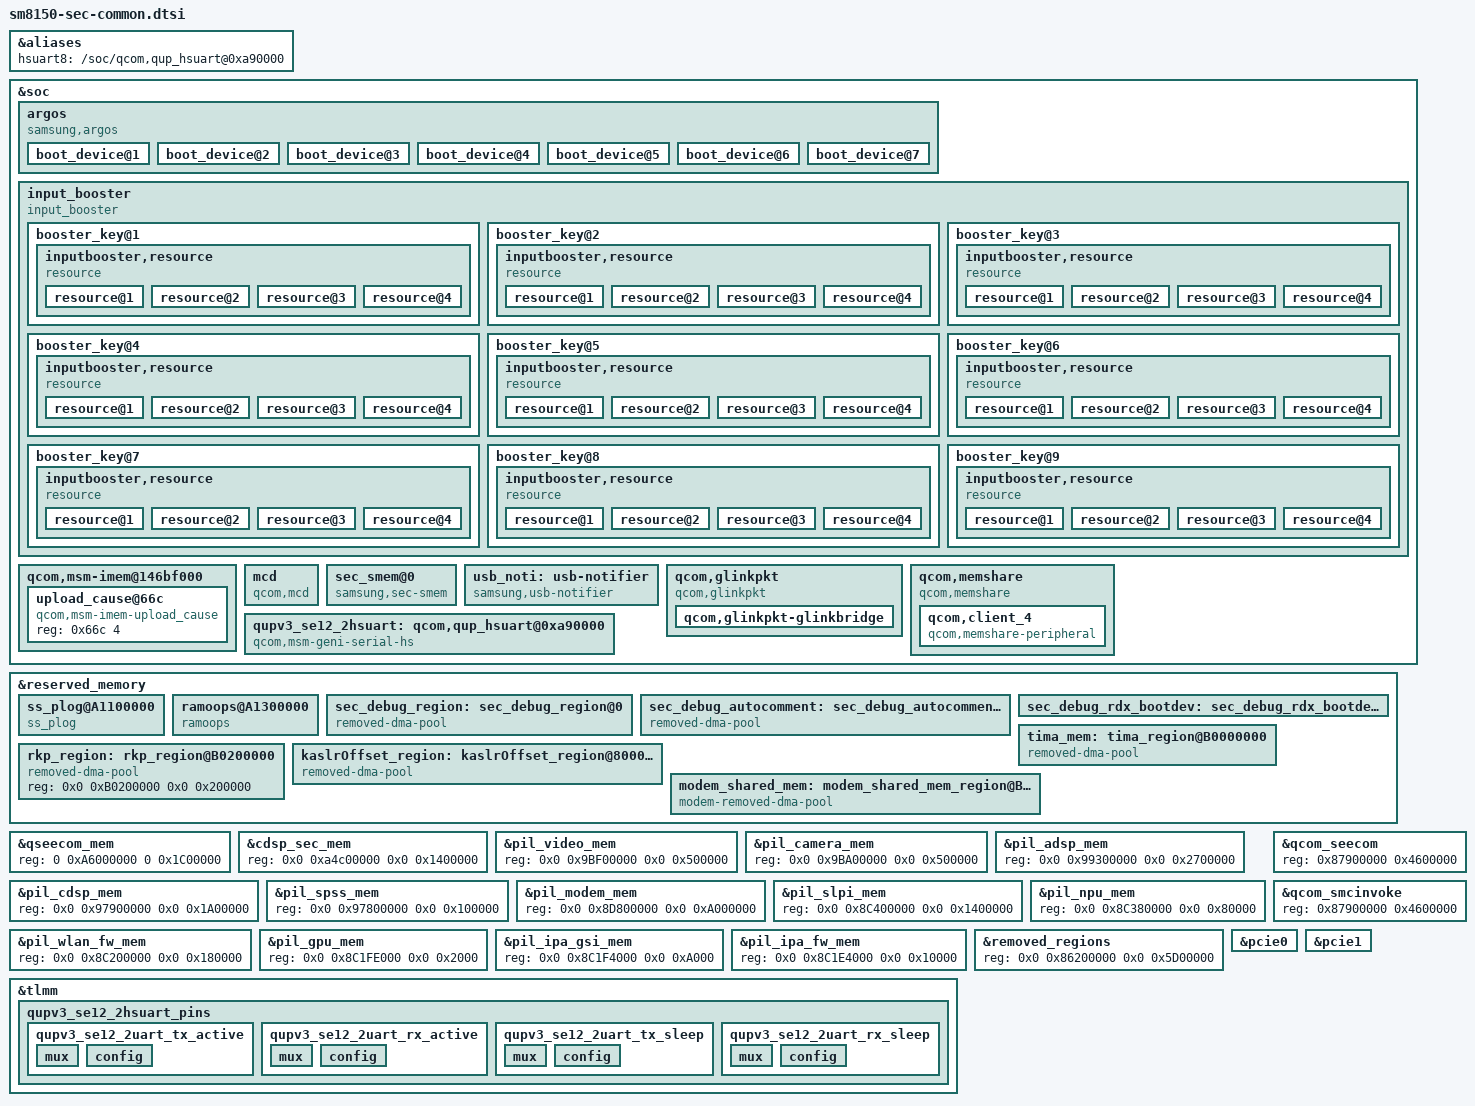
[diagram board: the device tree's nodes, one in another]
/* Copyright (c) 2016-2018, The Linux Foundation. All rights reserved.
 *
 * This program is free software; you can redistribute it and/or modify
 * it under the terms of the GNU General Public License version 2 and
 * only version 2 as published by the Free Software Foundation.
 *
 * This program is distributed in the hope that it will be useful,
 * but WITHOUT ANY WARRANTY; without even the implied warranty of
 * MERCHANTABILITY or FITNESS FOR A PARTICULAR PURPOSE.  See the
 * GNU General Public License for more details.
 */

#include "sm8150-sec-dcc.dtsi"

&aliases {
		hsuart8 = "/soc/qcom,qup_hsuart@0xa90000";
};

&soc {
	argos: argos {
		compatible = "samsung,argos";
		#address-cells = <1>;
		/* The device number should be assigned for each device, e.g. "boot_device@1" and "boot_device@2".
		 * Duplicated number is not allowed. Please refer the below example.
		 */
		/* Table Format should be
		 * <Throughput(Mbps) ARM_min ARM_max Little_min Little_max BIMC1 BIMC1 Task IRQ SCHED_boost>
		 * ARM_min : Big Core's minimum frequency lock. 0 means not set,
		 * ARM_max : Big Core's maximum frequency lock. 0 means not set,
		 * Little_min : Little Core's minimum frequency lock. 0 means not set,
		 * Little_max : Little Core's maximum frequency lock. 0 means not set,
		 * BIMC1 : Memory frequency lock. 0 means not set,(not used now)
		 * BIMC2 : Memory frequency lock. 0 means not set, (not used now)
		 * Task : 1 - Set task affinity lock.
		 *	0 - Not set or unlock,
		 *		Task affinity should be predefined driver's code.
		 * IRQ : 1 - Set irq affinity lock.
		 *       0 - Not set or unlock,
		 *		Task affinity should be predefined driver's code.
		 * SCHED_boost : 1 - Increase sched boosting count (not used now)
		 *             0 - Decrease sched boosting count
		 */
		/*
		 *boot_device@1 {
		 *		net_boost,label="WIFI";
		 *		net_boost,node="wlan0";
		 *		net_boost,table_size = <3>;
		 *		net_boost,table= <
		 *			5  2016000 0 2016000 0 0 0 0 0 0
		 *			10  2016000 0 2016000 0 0 0 0 0 0
		 *			20  2016000 0 2016000 0 0 0 0 0 0
		 *			30  2016000 0 2016000 0 0 0 0 0 0
		 *			>;
		 * };
		 */
		boot_device@1 {
			net_boost,label="WIFI TX";
			net_boost,node="wlan0";
			net_boost,table_size = <5>;
			net_boost,table= <
				20 1478400 0 1478400 0 0 0 0 0 0
				60 1708800 0 1708800 0 0 0 0 0 0
				100 1920000 0 1785600 0 0 0 0 0 1
				150 2227200 0 2227200 0 0 0 1 1 1
				300 2419200 0 2419200 0 0 0 1 1 1
				>;
		};
		boot_device@2 {
			net_boost,label="WIFI RX";
			net_boost,node="wlan0";
			net_boost,table_size = <4>;
			net_boost,table= <
				60 1113600 0 1113600 0 0 0 0 0 0
				100 1209600 0 1209600 0 0 0 0 0 0
				200 1804800 0 1785600 0 0 0 1 1 1
				300 2016000 0 2016000 0 0 0 1 1 1
				>;
		};
		boot_device@3 {
			net_boost,label="SWLAN";
			net_boost,node="swlan0";
			net_boost,table_size = <4>;
			net_boost,table= <
				2 1612800 0 1612800 0 0 0 0 0 0
				5 1843200 0 1843200 0 0 0 0 0 0
				20 2092800 0 2092800 0 0 0 1 1 1
				50 2246400 0 2246400 0 0 0 1 1 1
				>;
		};
		boot_device@4 {
			net_boost,label="UFS";
			net_boost,node="";
			net_boost,sysnode="/sys/class/scsi_host/host0/transferred_cnt";
			net_boost,table_size = <3>;
			net_boost,table= <
				112 0 0 566400 0 0 0 0 0 0
				800 0 0 883200 0 0 0 0 0 0
				3200 0 0 2092800 0 0 0 0 0 0
				>;
		};
		boot_device@5 {
			net_boost,label="P2P";
			net_boost,node="p2p-wlan0-0";
			net_boost,table_size = <3>;
			net_boost,table= <
				30 1420800 0 1420800 0 0 0 0 0 0
				90 1958400 0 1958400 0 0 0 0 0 0
				300 2208000 0 2208000 0 0 0 1 1 1
				>;
		};
		boot_device@6 {
			net_boost,label="NAN";
			net_boost,node="aware_data0";
			net_boost,table_size = <3>;
			net_boost,table= <
				30 1420800 0 1420800 0 0 0 0 0 0
				90 1958400 0 1958400 0 0 0 0 0 0
				300 2208000 0 2208000 0 0 0 1 1 1
				>;
		};
		boot_device@7 {
			net_boost,label="IPC";
			net_boost,node="rmnet_ipa0";
			net_boost,table_size = <6>;
			net_boost,table= <
				10 0 0 0 0 0 0 0 0 0
				30 1190400 0 1190400 0 0 0 0 0 0
				60 1420800 0 1420800 0 0 0 0 0 0
				100 1708800 0 1708800 0 0 0 0 0 0
				200 1804800 0 1804800 0 0 0 1 1 1
				300 2035200 0 2035200 0 0 0 1 1 1
			>;
		};
	};
};

&reserved_memory {
	/*
	 * Note: For TZapp, need to change XBL(QseeComDxe.h) and
	 *       TZ(oem_config.xml), too.
	 */

	ss_plog@A1100000 {
		compatible = "ss_plog";
		no-map;
		reg = <0x0 0xC1100000 0x0 0x00200000>;
	};
		
	ramoops@A1300000 {
		compatible = "ramoops";
		reg = <0 0xC1300000 0 0x100000>;
		record-size = <0x40000>;
		console-size = <0x40000>;
		ftrace-size = <0x40000>;
		pmsg-size = <0x40000>;
	};
		
	/* CONFIG_SEC_DEBUG reserves 8MB */
	sec_debug_region: sec_debug_region@0 {
		compatible = "removed-dma-pool";
		no-map;
		reg = <0x0 0xC1400000 0x0 0x00800000>;
	};
		
	sec_debug_autocomment: sec_debug_autocomment@0 {
		compatible = "removed-dma-pool";
		no-map;
		reg = <0x0 0xC1C00000 0x0 0x00001000>;
	};

	sec_debug_rdx_bootdev: sec_debug_rdx_bootdev@0 {
		no-ship;
		reg = <0x1 0x00000000 0x0 0x0AD00000>;
	};

	/*to reserve 2MB for TIMA */
	tima_mem: tima_region@B0000000 {
		compatible = "removed-dma-pool";
		no-map;
		reg = <0 0xB0000000 0 0x200000>;
	};

	/* rkp_region reserves for RKP */
	rkp_region: rkp_region@B0200000 {
		compatible = "removed-dma-pool";
		reg = <0x0 0xB0200000 0x0 0x200000>;
	};

	/* Kaslr offset reserve */
	kaslrOffset_region: kaslrOffset_region@80001000 {
		compatible = "removed-dma-pool";
		no-map;
		reg = <0x0 0x80001000 0x0 0x00001000>;
	};	

	modem_shared_mem: modem_shared_mem_region@B6C00000 {
		compatible = "modem-removed-dma-pool";
		no-map;
		reg = <0x0 0xb3900000 0x0 0x6000000>;
	};
};

&qseecom_mem {
	reg = <0 0xA6000000 0 0x1C00000>;
};
&cdsp_sec_mem {
	reg = <0x0 0xa4c00000 0x0 0x1400000>;
};
&pil_video_mem {
	reg = <0x0 0x9BF00000 0x0 0x500000>;
};
&pil_camera_mem {
	reg = <0x0 0x9BA00000 0x0 0x500000>;
};
&pil_adsp_mem {
	reg = <0x0 0x99300000 0x0 0x2700000>;
};
&pil_cdsp_mem {
	reg = <0x0 0x97900000 0x0 0x1A00000>;
};
&pil_spss_mem {
	reg = <0x0 0x97800000 0x0 0x100000>;
};
&pil_modem_mem {
	reg = <0x0 0x8D800000 0x0 0xA000000>;
};
&pil_slpi_mem {
	reg = <0x0 0x8C400000 0x0 0x1400000>;
};
&pil_npu_mem {
	reg = <0x0 0x8C380000 0x0 0x80000>;
};
&pil_wlan_fw_mem {
	reg = <0x0 0x8C200000 0x0 0x180000>;
	status = "ok";
};
&pil_gpu_mem {
	reg = <0x0 0x8C1FE000 0x0 0x2000>;
};
&pil_ipa_gsi_mem {
	reg = <0x0 0x8C1F4000 0x0 0xA000>;
};
&pil_ipa_fw_mem {
	reg = <0x0 0x8C1E4000 0x0 0x10000>;
};

&removed_regions {
	reg = <0x0 0x86200000 0x0 0x5D00000>;
};

/* TZapp region */
/* only for compatibility, not used for qcom,appsbl-qseecom-support */
&qcom_seecom {
	reg = <0x87900000 0x4600000>;
};
/* only for compatibility, there is no handling routine for reg in SMCinvoke driver */
&qcom_smcinvoke {
	reg = <0x87900000 0x4600000>;
};

&soc {
	input_booster {
		status = "okay";
		compatible = "input_booster";
		resValcount = "2";
		max_resource_count = "4";
		#address-cells = <1>;
		#size-cells = <0>;

		/* < CPU, DDR, HMP, LPM > */
		ib_release_values = "-1,0,0,0";

		booster_key@1 {
			input_booster,label = "key";
			input_booster,type = <0>;	/* BOOSTER_DEVICE_KEY */

			/* Time table */
			input_booster,head_time = <500>;
			input_booster,tail_time = <0>;

			/* Resource Table Sequentially identified with index
			 * CPU's ID & Index : 0
			 * DDR's ID & Index : 1
			 * HMP's ID & Index : 2
			 * LPM's ID & Index : 3
			*/

			/* Input Booster Resource Frequency */
			inputbooster,resource {
				compatible = "resource";
				resource@1 {
					resource,label = "CPU";
					resource,value = <1132800 0>;
				};

				resource@2 {
					resource,label = "DDR";
					resource,value = <0 0>;
				};

				resource@3 {
					resource,label = "HMP";
					resource,value = <2 0>;
				};

				resource@4 {
					resource,label = "LPM";
					resource,value = <0 0>;
				};
			};
		};
		booster_key@2 {
			input_booster,label = "touchkey";
			input_booster,type = <1>;	/* BOOSTER_DEVICE_TOUCHKEY */

			/* Time table */
			input_booster,head_time = <1>;
			input_booster,tail_time = <500>;

			/* Input Booster Resource Frequency */
			inputbooster,resource {
				compatible = "resource";
				resource@1 {
					resource,label = "CPU";
					resource,value = <1132800 0>;
				};

				resource@2 {
					resource,label = "DDR";
					resource,value = <0 0>;
				};

				resource@3 {
					resource,label = "HMP";
					resource,value = <2 0>;
				};

				resource@4 {
					resource,label = "LPM";
					resource,value = <0 0>;
				};
			};
		};
		booster_key@3 {
			input_booster,label = "touch";
			input_booster,type = <2>;	/* BOOSTER_DEVICE_TOUCH */

			/* Time table */
			input_booster,head_time = <200>;
			input_booster,tail_time = <300>;

			/* Input Booster Resource Frequency */
			inputbooster,resource {
				compatible = "resource";
				resource@1 {
					resource,label = "CPU";
					resource,value = <1132800 960000>;
				};

				resource@2 {
					resource,label = "DDR";
					resource,value = <1017 1017>;
				};

				resource@3 {
					resource,label = "HMP";
					resource,value = <2 2>;
				};

				resource@4 {
					resource,label = "LPM";
					resource,value = <5 5>;
				};
			};
		};
		booster_key@4 {
			input_booster,label = "multitouch";
			input_booster,type = <3>;	/* BOOSTER_DEVICE_MULTITOUCH */

			/* Time table */
			input_booster,head_time = <200>;
			input_booster,tail_time = <800>;

			/* Input Booster Resource Frequency */
			inputbooster,resource {
				compatible = "resource";
				resource@1 {
					resource,label = "CPU";
					resource,value = <1958400 1344000>;
				};

				resource@2 {
					resource,label = "DDR";
					resource,value = <0 0>;
				};

				resource@3 {
					resource,label = "HMP";
					resource,value = <2 2>;
				};

				resource@4 {
					resource,label = "LPM";
					resource,value = <0 0>;
				};
			};
		};
		booster_key@5 {
			input_booster,label = "keyboard";
			input_booster,type = <4>;	/* BOOSTER_DEVICE_KEYBOARD */

			/* Time table */
			input_booster,head_time = <130>;
			input_booster,tail_time = <130>;

			/* Input Booster Resource Frequency */
			inputbooster,resource {
				compatible = "resource";
				resource@1 {
					resource,label = "CPU";
					resource,value = <1132800 1132800>;
				};

				resource@2 {
					resource,label = "DDR";
					resource,value = <0 0>;
				};

				resource@3 {
					resource,label = "HMP";
					resource,value = <2 2>;
				};

				resource@4 {
					resource,label = "LPM";
					resource,value = <0 0>;
				};
			};
		};
		booster_key@6 {
			input_booster,label = "mouse";
			input_booster,type = <5>;	/* BOOSTER_DEVICE_MOUSE */

			/* Time table */
			input_booster,head_time = <200>;
			input_booster,tail_time = <300>;

			/* Input Booster Resource Frequency */
			inputbooster,resource {
				compatible = "resource";
				resource@1 {
					resource,label = "CPU";
					resource,value = <1132800 489600>;
				};

				resource@2 {
					resource,label = "DDR";
					resource,value = <0 0>;
				};

				resource@3 {
					resource,label = "HMP";
					resource,value = <2 0>;
				};

				resource@4 {
					resource,label = "LPM";
					resource,value = <0 0>;
				};
			};
		};
		booster_key@7 {
			input_booster,label = "mouse_wheel";
			input_booster,type = <6>;	/* BOOSTER_DEVICE_MOUSE */

			/* Time table */
			input_booster,head_time = <200>;
			input_booster,tail_time = <0>;

			/* Input Booster Resource Frequency */
			inputbooster,resource {
				compatible = "resource";
				resource@1 {
					resource,label = "CPU";
					resource,value = <1132800 0>;
				};

				resource@2 {
					resource,label = "DDR";
					resource,value = <0 0>;
				};

				resource@3 {
					resource,label = "HMP";
					resource,value = <2 0>;
				};

				resource@4 {
					resource,label = "LPM";
					resource,value = <0 0>;
				};
			};
		};
		booster_key@8 {
			input_booster,label = "pen_hover";
			input_booster,type = <7>;	/* BOOSTER_DEVICE_MOUSE */

			/* Time table */
			input_booster,head_time = <200>;
			input_booster,tail_time = <300>;

			/* Input Booster Resource Frequency */
			inputbooster,resource {
				compatible = "resource";
				resource@1 {
					resource,label = "CPU";
					resource,value = <1132800 489600>;
				};

				resource@2 {
					resource,label = "DDR";
					resource,value = <0 0>;
				};

				resource@3 {
					resource,label = "HMP";
					resource,value = <2 0>;
				};

				resource@4 {
					resource,label = "LPM";
					resource,value = <0 0>;
				};
			};
		};
		booster_key@9 {
			input_booster,label = "pen";
			input_booster,type = <8>;	/* BOOSTER_DEVICE_MOUSE */

			/* Time table */
			input_booster,head_time = <200>;
			input_booster,tail_time = <600>;

			/* Input Booster Resource Frequency */
			inputbooster,resource {
				compatible = "resource";
				resource@1 {
					resource,label = "CPU";
					resource,value = <1574400 960000>;
				};

				resource@2 {
					resource,label = "DDR";
					resource,value = <0 0>;
				};

				resource@3 {
					resource,label = "HMP";
					resource,value = <2 2>;
				};

				resource@4 {
					resource,label = "LPM";
					resource,value = <0 0>;
				};
			};
		};
		/* If you need to add new key type, add it this position */
	};
};

&soc {
	qcom,msm-imem@146bf000 {
		upload_cause@66c {
		compatible = "qcom,msm-imem-upload_cause";
		reg = <0x66c 4>;
		};
	};

	mcd {
		compatible = "qcom,mcd";
		qcom,ce-hw-instance = <0>;
		qcom,ce-device = <0>;
		interrupts = <0 640 0>;
		interrupt-names = "mcd_irq";
		qcom,no-clock-support;
	};

	sec_smem@0 {
		compatible = "samsung,sec-smem";
		status = "okay";
	};

	usb_noti: usb-notifier {
		compatible = "samsung,usb-notifier";
		qcom,disable_control_en = <1>;
		qcom,unsupport_host_en = <0>;
	};
	
	qcom,glinkpkt {
		compatible = "qcom,glinkpkt";

		qcom,glinkpkt-glinkbridge {
			qcom,glinkpkt-transport = "smem";
			qcom,glinkpkt-edge = "mpss";
			qcom,glinkpkt-ch-name = "glink_bridge";
			qcom,glinkpkt-dev-name = "smd4";
		};
	};

	qcom,memshare {
		compatible = "qcom,memshare";

		qcom,client_4 {
			compatible = "qcom,memshare-peripheral";
			memory-region = <&modem_shared_mem>;
			qcom,peripheral-size = <0x02000000>;
			qcom,reserved-size = <0x04000000>;
			qcom,client-id = <3>;
			qcom,allocate-boot-time;
			label = "modem";
		};
	};

	qupv3_se12_2hsuart: qcom,qup_hsuart@0xa90000 {
		compatible = "qcom,msm-geni-serial-hs", "qcom,msm-geni-uart";
		reg = <0xa90000 0x4000>;
		reg-names = "se_phys";
		clock-names = "se-clk", "m-ahb", "s-ahb";
		clocks = <&clock_gcc GCC_QUPV3_WRAP1_S4_CLK>,
		<&clock_gcc GCC_QUPV3_WRAP_1_M_AHB_CLK>,
		<&clock_gcc GCC_QUPV3_WRAP_1_S_AHB_CLK>;
		pinctrl-names = "default", "sleep";
		pinctrl-0 = <&qupv3_se12_2uart_tx_active>, <&qupv3_se12_2uart_rx_active>;
		pinctrl-1 = <&qupv3_se12_2uart_tx_sleep>, <&qupv3_se12_2uart_rx_sleep>;
		interrupts = <GIC_SPI 357 0>;
		qcom,wrapper-core = <&qupv3_1>;
		status = "ok";
		always-on-clock;
	};
};

&pcie0 {
	qcom,target-link-speed = <0x1>;

	l1ss-ltr-max-snoop-latency = <0x10031003>;
	l1ss-tpoweron = <0x69>; /* 130us */
	l1ss-ltr-l1p2-threshold = <0x40a0>; /* 164us : scale 1024ns, threshold 0xa0 */

	qcom,ep-latency = <0>;

	qcom,common-clk-en;
	qcom,clk-power-manage-en;
	qcom,core-preset = <0x77777777>;
};

&pcie1 {
	qcom,ep-latency = <0>;
	qcom,core-preset = <0x77777777>;
};

&tlmm {
	qupv3_se12_2hsuart_pins: qupv3_se12_2hsuart_pins {
		qupv3_se12_2uart_tx_active: qupv3_se12_2uart_tx_active {
			mux {
				pins = "gpio85";
				function = "qup12";
			};

			config {
				pins = "gpio85";
				drive-strength = <2>;
				bias-pull-up;
			};
		};
	
		qupv3_se12_2uart_rx_active: qupv3_se12_2uart_rx_active {
			mux {
				pins = "gpio86";
				function = "qup12";
			};

			config {
				pins = "gpio86";
				drive-strength = <2>;
				bias-pull-down;
			};
		};

		qupv3_se12_2uart_tx_sleep: qupv3_se12_2uart_tx_sleep {
			mux {
				pins = "gpio85";
				function = "gpio";
			};

			config {
				pins = "gpio85";
				drive-strength = <2>;
				bias-pull-up;
				input-enable;
			};
		};

		qupv3_se12_2uart_rx_sleep: qupv3_se12_2uart_rx_sleep {
			mux {
				pins = "gpio86";
				function = "gpio";
			};

			config {
				pins = "gpio86";
				drive-strength = <2>;
				bias-pull-down;
			};
		};
	};
};
